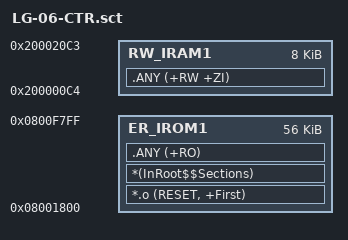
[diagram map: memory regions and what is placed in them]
; *************************************************************
; *** Scatter-Loading Description File generated by uVision ***
; *************************************************************

LR_IROM1 0x08001800 0x0000E000  {    ; load region size_region
  ER_IROM1 0x08001800 0x0000E000  {  ; load address = execution address
   *.o (RESET, +First)
   *(InRoot$$Sections)
   .ANY (+RO)
  }
  RW_IRAM1 0x200000C4 0x00002000  {  ; RW data
   .ANY (+RW +ZI)
  }
}

